# va416xx register map
Vendor: VORAGO TECHNOLOGIES; Series: M4; File version: 1.3
CPU: CM4 r0p1, little endian, no MPU, FPU, 4 interrupt priority bits
Registers are 32-bit, read-write, reset 0x0 unless marked. A register's access mark holds for its fields unless they carry their own. Offsets are from the block's base; [hi:lo] are bit positions; 'fields as' and 'values as' point back to an identical list.

## UART0 — UART Peripheral
Base 0x40024000
Same registers: UART2 0x40017000, UART1 0x40025000
0x00 DATA — Data In/Out Register
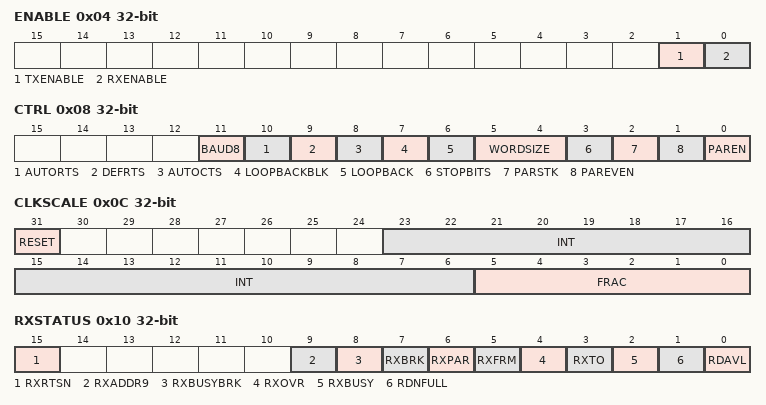
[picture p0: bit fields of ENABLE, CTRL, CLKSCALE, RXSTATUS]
0x04 ENABLE
  [1] TXENABLE, [0] RXENABLE
0x08 CTRL — Control Register
  [11] BAUD8 — Enable BAUD8 mode
  [10] AUTORTS — Enable Auto RTS mode
  [9] DEFRTS — Default RTSn value
  [8] AUTOCTS — Enable Auto CTS mode
  [7] LOOPBACKBLK — Loopback Block
  [6] LOOPBACK — Loopback Enable
  [5:4] WORDSIZE — Word Size in Bits 5/6/7/8(00/01/10/11)
  [3] STOPBITS — Stop Bits 1/2(0/1)
  [2] PARSTK — Parity Sticky
  [1] PAREVEN — Parity Even/Odd(1/0)
  [0] PAREN — Parity Enable
0x0C CLKSCALE — Clock Scale Register
  [31] RESET wo — Reset Baud Counter
  [23:6] INT — Integer Divide
  [5:0] FRAC — Fractional Divide (64ths)
0x10 RXSTATUS ro — Status Register
  [15] RXRTSN — RX RTSn Output Value
  [9] RXADDR9 — Address Match for 9 bit mode
  [8] RXBUSYBRK — RX Busy Receiving Break
  [7] RXBRK — RX Break Error
  [6] RXPAR — RX Parity Error
  [5] RXFRM — RX Framing Error
  [4] RXOVR — Read Fifo Overflow
  [3] RXTO — RX Receive Timeout
  [2] RXBUSY — RX Busy Receiving
  [1] RDNFULL — Read Fifo NOT Full
  [0] RDAVL — Read Data Available
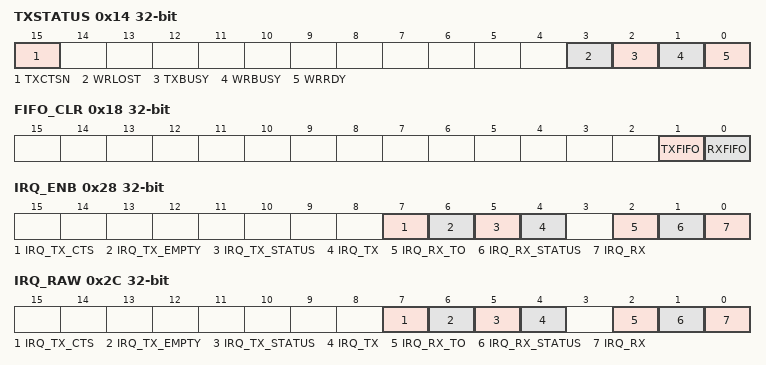
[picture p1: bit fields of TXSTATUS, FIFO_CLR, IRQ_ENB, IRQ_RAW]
0x14 TXSTATUS ro — Status Register
  [15] TXCTSN — TX CTSn Input Value
  [3] WRLOST — Write Data Lost (Fifo Overflow)
  [2] TXBUSY — TX Busy Transmitting
  [1] WRBUSY — Write Fifo Full
  [0] WRRDY — Write Fifo NOT Full
0x18 FIFO_CLR wo — Clear FIFO Register
  [1] TXFIFO — Clear Tx FIFO
  [0] RXFIFO — Clear Rx FIFO
0x1C TXBREAK wo — Break Transmit Register
0x20 ADDR9 — Address9 Register
0x24 ADDR9MASK — Address9 Mask Register
0x28 IRQ_ENB — IRQ Enable Register
  [7] IRQ_TX_CTS — TX CTS Change Interrupt
  [6] IRQ_TX_EMPTY — TX Empty Interrupt
  [5] IRQ_TX_STATUS — TX Status Interrupt
  [4] IRQ_TX — TX Interrupt
  [2] IRQ_RX_TO — RX Timeout Interrupt
  [1] IRQ_RX_STATUS — RX Status Interrupt
  [0] IRQ_RX — RX Interrupt
0x2C IRQ_RAW ro — IRQ Raw Status Register
  fields as IRQ_ENB
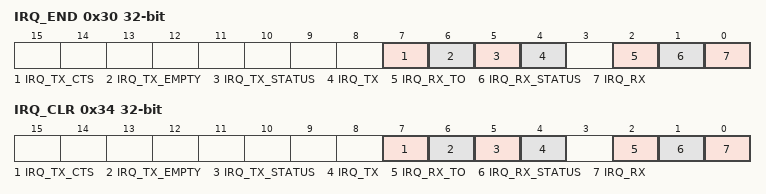
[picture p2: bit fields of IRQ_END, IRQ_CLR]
0x30 IRQ_END ro — IRQ Enabled Status Register
  fields as IRQ_ENB
0x34 IRQ_CLR wo — IRQ Clear Status Register
  fields as IRQ_ENB
0x38 RXFIFOIRQTRG — Rx FIFO IRQ Trigger Level
0x3C TXFIFOIRQTRG — Tx FIFO IRQ Trigger Level
0x40 RXFIFORTSTRG — Rx FIFO RTS Trigger Level
0x44 STATE ro — Internal STATE of UART Controller
0xFFC PERID ro reset 0x21207E9 — Peripheral ID Register

## SPI0 — SPI Peripheral
Base 0x40015000
Same registers: SPI1 0x40015400, SPI2 0x40015800, SPI3 0x40015C00
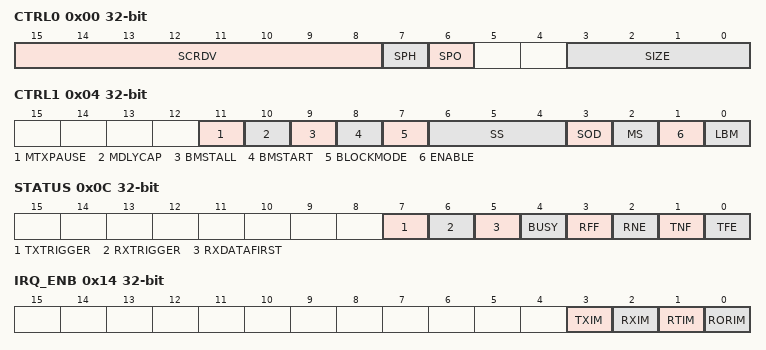
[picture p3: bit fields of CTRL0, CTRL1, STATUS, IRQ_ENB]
0x00 CTRL0 — Control Register 0
  [15:8] SCRDV — Serial Clock Rate divide+1 value
  [7] SPH — SPI Clock Phase
  [6] SPO — SPI Clock Polarity
  [3:0] SIZE — Data Size(0x3=>4, 0xf=>16)
0x04 CTRL1 — Control Register 1
  [11] MTXPAUSE — Master Tx Pause Enable
  [10] MDLYCAP — Master Delayed Capture Enable
  [9] BMSTALL — Block Mode Stall Enable
  [8] BMSTART — Block Mode Start Status Enable
  [7] BLOCKMODE — Block Mode Enable
  [6:4] SS — Slave Select
  [3] SOD — Slave output Disable
  [2] MS — Master/Slave (0:Master, 1:Slave)
  [1] ENABLE
  [0] LBM — Loop Back
0x08 DATA — Data Input/Output
0x0C STATUS ro
  [7] TXTRIGGER — TX FIFO Below Trigger Level
  [6] RXTRIGGER — RX FIFO Above Trigger Level
  [5] RXDATAFIRST — Pending Data is first Byte in BLOCKMODE
  [4] BUSY
  [3] RFF — Receive FIFO Full
  [2] RNE — Receive FIFO not empty
  [1] TNF — Transmit FIFO not full
  [0] TFE — Transmit FIFO empty
0x10 CLKPRESCALE — Clock Pre Scale divide value
0x14 IRQ_ENB — Interrupt Enable Register
  [3] TXIM — TX Fifo is at least half empty
  [2] RXIM — RX Fifo is at least half full
  [1] RTIM — RX Timeout
  [0] RORIM — RX Overrun
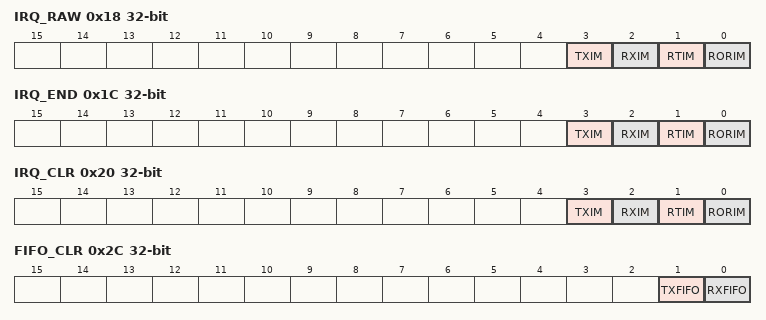
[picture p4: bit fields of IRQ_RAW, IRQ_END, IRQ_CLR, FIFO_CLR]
0x18 IRQ_RAW ro — Raw Interrupt Status Register
  fields as IRQ_ENB
0x1C IRQ_END ro — Enabled Interrupt Status Register
  fields as IRQ_ENB
0x20 IRQ_CLR wo write-1-clears — Clear Interrupt Status Register
  fields as IRQ_ENB
0x24 RXFIFOIRQTRG — Rx FIFO IRQ Trigger Level
0x28 TXFIFOIRQTRG — Tx FIFO IRQ Trigger Level
0x2C FIFO_CLR wo — Clear FIFO Register
  [1] TXFIFO — Clear Tx FIFO
  [0] RXFIFO — Clear Rx FIFO
0x30 STATE ro — Internal STATE of SPI Controller
0x3FC PERID ro reset 0x21307E9 — Peripheral ID Register
